AUTOSAR XML (schema 00046)
package /VRM_InputsReading_pkg/VRM_InputsReading_imp
  swc implementation VRM_InputsReading: behavior=VRM_InputsReading
    code-descriptors:
      code Default: artifact-descriptors=autosar-engineering-object=category=SWSRC
package /VRM_InputsReading_pkg/VRM_InputsReading_swc
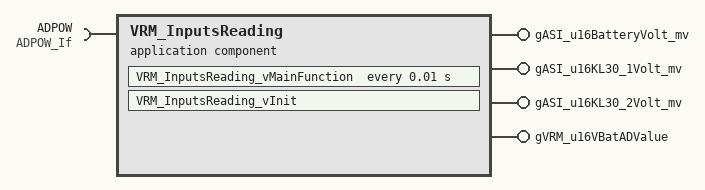
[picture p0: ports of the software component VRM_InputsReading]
  application sw component type VRM_InputsReading
    4 x provide port, all with nonqueued-sender-com-spec{data-element=Val, init-value=0}:
      gASI_u16BatteryVolt_mv: provided-interface=gASI_u16BatteryVolt_mv
      gASI_u16KL30_1Volt_mv: provided-interface=gASI_u16KL30_1Volt_mv
      gASI_u16KL30_2Volt_mv: provided-interface=gASI_u16KL30_2Volt_mv
      gVRM_u16VBatADValue: provided-interface=gVRM_u16VBatADValue
    require port ADPOW: required-interface=ADPOW_If
      required-com-specs:
        data-element=AD_KL30_1_FV, filter=data-filter-type=ALWAYS
        data-element=AD_VPUP1_FV, filter=data-filter-type=ALWAYS
        data-element=AD_VPUP2_FV, filter=data-filter-type=ALWAYS
        data-element=AD_KL30_2_FV, filter=data-filter-type=ALWAYS
        data-element=AD_VPUP3_FV, filter=data-filter-type=ALWAYS
        data-element=AD_SLC_POWER_FV, filter=data-filter-type=ALWAYS
    behavior VRM_InputsReading
      timing event PeriodicEvent: start-on-event=VRM_InputsReading_vMainFunction, period=0.01
      port-api-options:
        enable-take-address=true, error-handling=NO-TRANSFORMER-ERROR-HANDLING, indirect-api=true, port=ADPOW
        enable-take-address=false, error-handling=NO-TRANSFORMER-ERROR-HANDLING, indirect-api=false, port=gASI_u16BatteryVolt_mv
        enable-take-address=false, error-handling=NO-TRANSFORMER-ERROR-HANDLING, indirect-api=false, port=gASI_u16KL30_1Volt_mv
        enable-take-address=false, error-handling=NO-TRANSFORMER-ERROR-HANDLING, indirect-api=false, port=gASI_u16KL30_2Volt_mv
        enable-take-address=false, error-handling=NO-TRANSFORMER-ERROR-HANDLING, indirect-api=false, port=gVRM_u16VBatADValue
      runnable VRM_InputsReading_vInit
      runnable VRM_InputsReading_vMainFunction
        data-receive-point-by-arguments:
          6 x access:
            REC_ADPOW_AD_KL30_1_FV: accessed-variable=ADPOW.AD_KL30_1_FV
            REC_ADPOW_AD_KL30_2_FV: accessed-variable=ADPOW.AD_KL30_2_FV
            REC_ADPOW_AD_SLC_POWER_FV: accessed-variable=ADPOW.AD_SLC_POWER_FV
            REC_ADPOW_AD_VPUP{1..3}_FV: accessed-variable=ADPOW.AD_VPUP{1..3}_FV
        data-send-points:
          4 x access:
            SEND_gASI_u16BatteryVolt_mv_Element: accessed-variable=gASI_u16BatteryVolt_mv.Val
            SEND_gASI_u16KL30_1Volt_mv_Element: accessed-variable=gASI_u16KL30_1Volt_mv.Val
            SEND_gASI_u16KL30_2Volt_mv_Element: accessed-variable=gASI_u16KL30_2Volt_mv.Val
            SEND_gVRM_u16VBatADValue_Val: accessed-variable=gVRM_u16VBatADValue.Val
